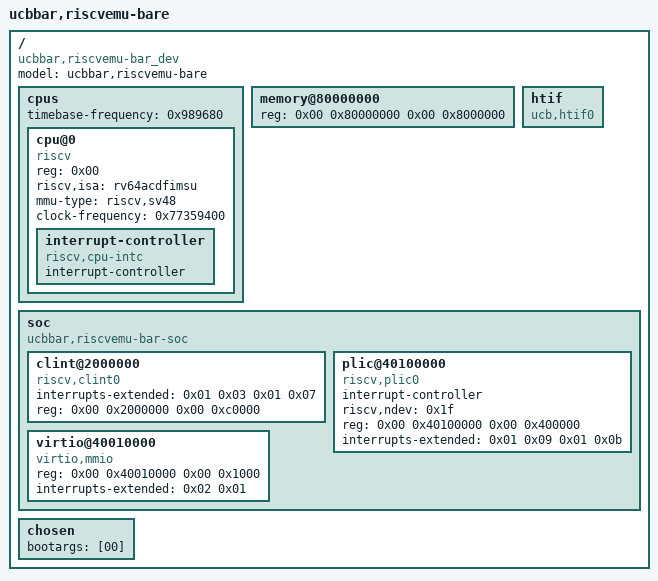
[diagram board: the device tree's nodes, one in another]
/dts-v1/;

/ {
	#address-cells = <0x02>;
	#size-cells = <0x02>;
	compatible = "ucbbar,riscvemu-bar_dev";
	model = "ucbbar,riscvemu-bare";

	cpus {
		#address-cells = <0x01>;
		#size-cells = <0x00>;
		timebase-frequency = <0x989680>;

		cpu@0 {
			device_type = "cpu";
			reg = <0x00>;
			status = "okay";
			compatible = "riscv";
			riscv,isa = "rv64acdfimsu";
			mmu-type = "riscv,sv48";
			clock-frequency = <0x77359400>;

			interrupt-controller {
				#interrupt-cells = <0x01>;
				interrupt-controller;
				compatible = "riscv,cpu-intc";
				phandle = <0x01>;
			};
		};
	};

	memory@80000000 {
		device_type = "memory";
		reg = <0x00 0x80000000 0x00 0x8000000>;
	};

	htif {
		compatible = "ucb,htif0";
	};

	soc {
		#address-cells = <0x02>;
		#size-cells = <0x02>;
		compatible = "ucbbar,riscvemu-bar-soc\0simple-bus";
		ranges;

		clint@2000000 {
			compatible = "riscv,clint0";
			interrupts-extended = <0x01 0x03 0x01 0x07>;
			reg = <0x00 0x2000000 0x00 0xc0000>;
		};

		plic@40100000 {
			#interrupt-cells = <0x01>;
			interrupt-controller;
			compatible = "riscv,plic0";
			riscv,ndev = <0x1f>;
			reg = <0x00 0x40100000 0x00 0x400000>;
			interrupts-extended = <0x01 0x09 0x01 0x0b>;
			phandle = <0x02>;
		};

		virtio@40010000 {
			compatible = "virtio,mmio";
			reg = <0x00 0x40010000 0x00 0x1000>;
			interrupts-extended = <0x02 0x01>;
		};
	};

	chosen {
		bootargs = [00];
	};
};
